VERSION ""

NS_ :

BS_:

BU_: DBG DRIVER IO MOTOR SENSOR MASTER GEO BLE

BO_ 1 BLE_START_STOP_CMD: 1 BLE
 SG_ BLE_START_STOP_CMD_start : 0|4@1+ (1,0) [0|1] "" MASTER
 SG_ BLE_START_STOP_CMD_reset : 4|4@1+ (1,0) [0|1] "" MASTER

BO_ 2 MASTER_SYS_STOP_CMD: 1 MASTER
 SG_ MASTER_SYS_STOP_CMD_stop : 0|8@1+ (1,0) [0|1] "" MOTOR

BO_ 212 BLE_GPS_DATA: 8 BLE
 SG_ BLE_GPS_long : 0|32@1- (0.000001,0) [0|0] "" GEO
 SG_ BLE_GPS_lat : 32|32@1- (0.000001,0) [0|0] "" GEO

BO_ 213 BLE_GPS_DATA_CNT: 1 BLE
 SG_ BLE_GPS_COUNT : 0|8@1+ (1,0) [0|0] "" GEO,SENSOR

BO_ 214 GEO_CURRENT_COORD: 8 GEO
 SG_ GEO_CURRENT_COORD_LONG : 0|32@1- (0.000001,0) [0|0] "" MASTER,BLE
 SG_ GEO_CURRENT_COORD_LAT : 32|32@1- (0.000001,0) [0|0] "" MASTER,BLE

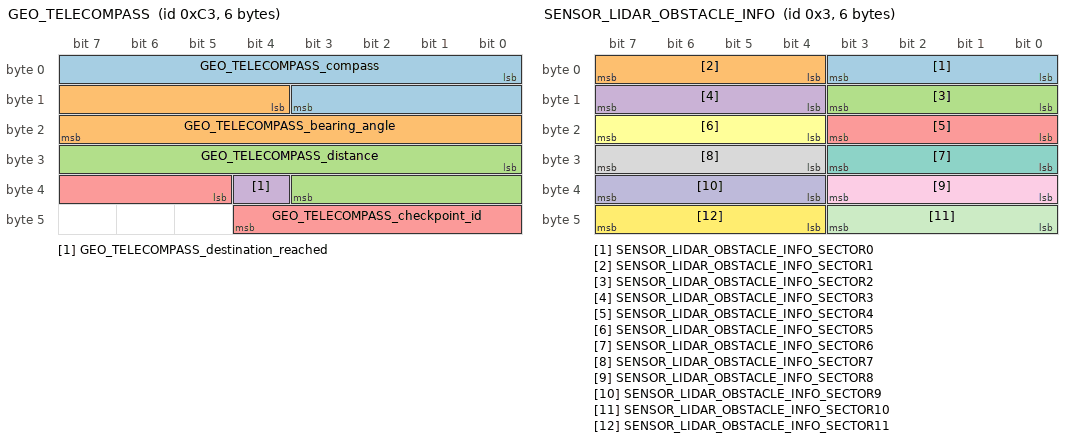
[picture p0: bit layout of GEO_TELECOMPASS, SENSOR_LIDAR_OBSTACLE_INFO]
BO_ 195 GEO_TELECOMPASS: 6 GEO
 SG_ GEO_TELECOMPASS_compass : 0|12@1+ (0.1,0) [0|360.0] "" MASTER,BLE
 SG_ GEO_TELECOMPASS_bearing_angle : 12|12@1+ (0.1,0) [0|360.0] "" MASTER,BLE
 SG_ GEO_TELECOMPASS_distance : 24|12@1+ (0.1,0) [0|0] "" MASTER,BLE
 SG_ GEO_TELECOMPASS_destination_reached : 36|1@1+ (1,0) [0|1] "" MASTER,BLE
 SG_ GEO_TELECOMPASS_checkpoint_id : 37|8@1+ (1,0) [0|0] "" MASTER,BLE,SENSOR

BO_ 196 GEO_TELEMETRY_LOCK: 1 GEO
 SG_ GEO_TELEMETRY_lock : 0|8@1+ (1,0) [0|0] "" MASTER,SENSOR,BLE

BO_ 197 BLE_CON_ST: 1 BLE
 SG_ BLE_ANDROID_CON_STATUS : 0|8@1+ (1,0) [0|0] "" SENSOR,MASTER

BO_ 3 SENSOR_LIDAR_OBSTACLE_INFO: 6 SENSOR
 SG_ SENSOR_LIDAR_OBSTACLE_INFO_SECTOR0 : 0|4@1+ (1,0) [0|12] "" MASTER,BLE
 SG_ SENSOR_LIDAR_OBSTACLE_INFO_SECTOR1 : 4|4@1+ (1,0) [0|12] "" MASTER,BLE
 SG_ SENSOR_LIDAR_OBSTACLE_INFO_SECTOR2 : 8|4@1+ (1,0) [0|12] "" MASTER,BLE
 SG_ SENSOR_LIDAR_OBSTACLE_INFO_SECTOR3 : 12|4@1+ (1,0) [0|12] "" MASTER,BLE
 SG_ SENSOR_LIDAR_OBSTACLE_INFO_SECTOR4 : 16|4@1+ (1,0) [0|12] "" MASTER,BLE
 SG_ SENSOR_LIDAR_OBSTACLE_INFO_SECTOR5 : 20|4@1+ (1,0) [0|12] "" MASTER,BLE
 SG_ SENSOR_LIDAR_OBSTACLE_INFO_SECTOR6 : 24|4@1+ (1,0) [0|12] "" MASTER,BLE
 SG_ SENSOR_LIDAR_OBSTACLE_INFO_SECTOR7 : 28|4@1+ (1,0) [0|12] "" MASTER,BLE
 SG_ SENSOR_LIDAR_OBSTACLE_INFO_SECTOR8 : 32|4@1+ (1,0) [0|12] "" MASTER,BLE
 SG_ SENSOR_LIDAR_OBSTACLE_INFO_SECTOR9 : 36|4@1+ (1,0) [0|12] "" MASTER,BLE
 SG_ SENSOR_LIDAR_OBSTACLE_INFO_SECTOR10 : 40|4@1+ (1,0) [0|12] "" MASTER,BLE
 SG_ SENSOR_LIDAR_OBSTACLE_INFO_SECTOR11 : 44|4@1+ (1,0) [0|12] "" MASTER,BLE

BO_ 17 MASTER_SPEED_STEER_CMD: 2 MASTER
 SG_ MASTER_SPEED_STEER_CMD_speed : 0|8@1- (1,0) [-100|100] "" MOTOR
 SG_ MASTER_SPEED_STEER_CMD_steer : 8|8@1- (1,0) [-100|100] "" MOTOR

BO_ 60 MASTER_SYS_START_CMD: 1 MASTER
 SG_ MASTER_SYS_START_CMD_start : 0|8@1+ (1,0) [0|1] "" SENSOR

BO_ 35 MOTOR_HEARTBEAT: 1 MOTOR
 SG_ MOTOR_HEARTBEAT_signal : 0|8@1+ (1,0) [0|255] "" MASTER

BO_ 36 SENSOR_HEARTBEAT: 1 SENSOR
 SG_ SENSOR_HEARTBEAT_signal : 0|8@1+ (1,0) [0|255] "" MASTER

BO_ 37 GEO_HEARTBEAT: 1 GEO
 SG_ GEO_HEARTBEAT_signal : 0|8@1+ (1,0) [0|255] "" MASTER

BO_ 38 BLE_HEARTBEAT: 1 BLE
 SG_ BLE_HEARTBEAT_signal : 0|8@1+ (1,0) [0|255] "" MASTER

BO_ 4 GEO_TURNING_ANGLE: 2 GEO
 SG_ GEO_TURNING_ANGLE_degree : 0|9@1- (1,0) [-180|180] "" MASTER,BLE

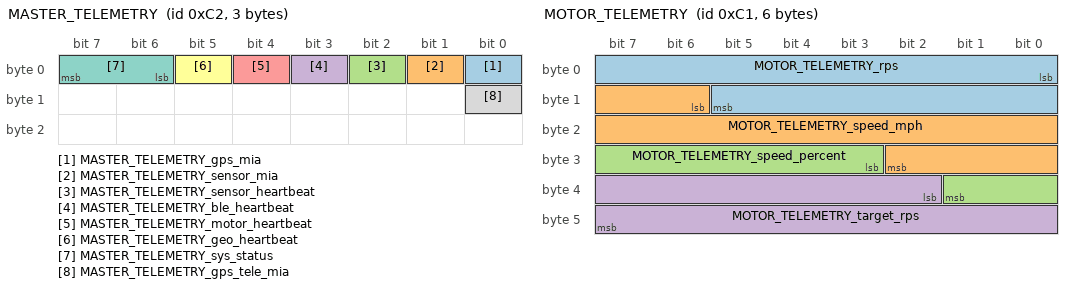
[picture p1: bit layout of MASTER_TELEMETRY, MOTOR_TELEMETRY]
BO_ 194 MASTER_TELEMETRY: 3 MASTER
 SG_ MASTER_TELEMETRY_gps_mia : 0|1@1+ (1,0) [0|1] "" BLE
 SG_ MASTER_TELEMETRY_sensor_mia : 1|1@1+ (1,0) [0|1] "" BLE
 SG_ MASTER_TELEMETRY_sensor_heartbeat : 2|1@1+ (1,0) [0|1] "" BLE
 SG_ MASTER_TELEMETRY_ble_heartbeat : 3|1@1+ (1,0) [0|1] "" BLE
 SG_ MASTER_TELEMETRY_motor_heartbeat : 4|1@1+ (1,0) [0|1] "" BLE
 SG_ MASTER_TELEMETRY_geo_heartbeat : 5|1@1+ (1,0) [0|1] "" BLE
 SG_ MASTER_TELEMETRY_sys_status : 6|2@1+ (1,0) [0|3] "" BLE
 SG_ MASTER_TELEMETRY_gps_tele_mia : 8|1@1+ (1,0) [0|1] "" BLE

BO_ 193 MOTOR_TELEMETRY: 6 MOTOR
 SG_ MOTOR_TELEMETRY_rps : 0|14@1+ (0.01,0) [0|100.00] "" MASTER
 SG_ MOTOR_TELEMETRY_speed_mph : 14|13@1+ (0.01,0) [0|70.00] "" MASTER
 SG_ MOTOR_TELEMETRY_speed_percent : 27|7@1+ (1,0) [0|100] "" MASTER
 SG_ MOTOR_TELEMETRY_target_rps : 34|14@1+ (0.01,0) [0|100.00] "" MASTER

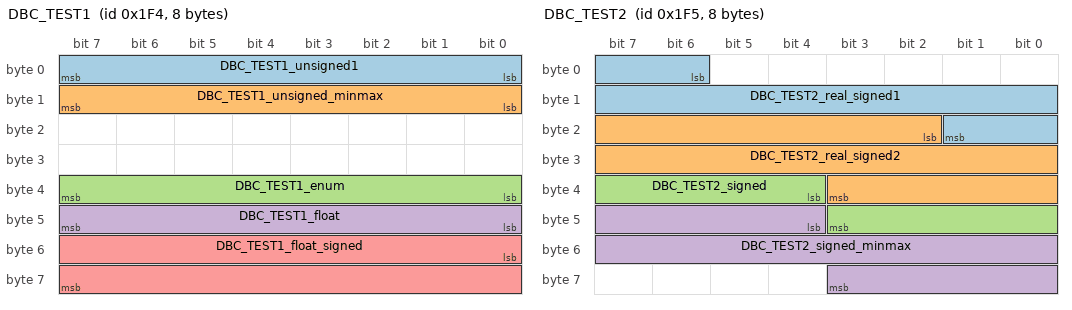
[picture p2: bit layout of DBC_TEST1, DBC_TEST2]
BO_ 500 DBC_TEST1: 8 IO
 SG_ DBC_TEST1_unsigned1 : 0|8@1+ (1,0) [0|0] "" DBG
 SG_ DBC_TEST1_unsigned_minmax : 8|8@1+ (1,0) [0|100] "" DBG
 SG_ DBC_TEST1_enum : 32|8@1+ (1,0) [0|0] "" DBG
 SG_ DBC_TEST1_float : 40|8@1+ (0.5,0) [0|0] "" DBG
 SG_ DBC_TEST1_float_signed : 48|16@1+ (0.001,0) [0|65.535] "" DBG

BO_ 501 DBC_TEST2: 8 IO
 SG_ DBC_TEST2_real_signed1 : 6|12@1- (1,0) [0|0] "" DBG
 SG_ DBC_TEST2_real_signed2 : 18|18@1- (1,0) [0|0] "" DBG
 SG_ DBC_TEST2_signed : 36|8@1+ (1,-128) [0|0] "" DBG
 SG_ DBC_TEST2_signed_minmax : 44|16@1+ (1,-32768) [-32768|32767] "" DBG

BO_ 502 DBC_TEST3: 8 IO
 SG_ DBC_TEST3_real_signed1 : 2|4@1- (1,-5) [0|0] "" DBG
 SG_ DBC_TEST3_real_signed2 : 8|8@1- (1,4) [0|0] "" DBG

BO_ 100 DRIVER_HEARTBEAT: 1 DRIVER
 SG_ DRIVER_HEARTBEAT_cmd : 0|8@1+ (1,0) [0|0] "" SENSOR,MOTOR

BO_ 101 MOTOR_CMD: 1 DRIVER
 SG_ MOTOR_CMD_steer : 0|4@1+ (1,-5) [-5|5] "" MOTOR
 SG_ MOTOR_CMD_drive : 4|4@1+ (1,0) [0|9] "" MOTOR

BO_ 400 MOTOR_STATUS: 3 MOTOR
 SG_ MOTOR_STATUS_wheel_error : 0|1@1+ (1,0) [0|0] "" DRIVER,IO
 SG_ MOTOR_STATUS_speed_kph : 8|16@1+ (0.001,0) [0|0] "kph" DRIVER,IO

BO_ 200 SENSOR_SONARS: 8 SENSOR
 SG_ SENSOR_SONARS_mux M : 0|4@1+ (1,0) [0|0] "" DRIVER,IO
 SG_ SENSOR_SONARS_err_count : 4|12@1+ (1,0) [0|0] "" DRIVER,IO
 SG_ SENSOR_SONARS_left m0 : 16|12@1+ (0.1,0) [0|0] "" DRIVER,IO
 SG_ SENSOR_SONARS_middle m0 : 28|12@1+ (0.1,0) [0|0] "" DRIVER,IO
 SG_ SENSOR_SONARS_right m0 : 40|12@1+ (0.1,0) [0|0] "" DRIVER,IO
 SG_ SENSOR_SONARS_rear m0 : 52|12@1+ (0.1,0) [0|0] "" DRIVER,IO
 SG_ SENSOR_SONARS_no_filt_left m1 : 16|12@1+ (0.1,0) [0|0] "" DBG
 SG_ SENSOR_SONARS_no_filt_middle m1 : 28|12@1+ (0.1,0) [0|0] "" DBG
 SG_ SENSOR_SONARS_no_filt_right m1 : 40|12@1+ (0.1,0) [0|0] "" DBG
 SG_ SENSOR_SONARS_no_filt_rear m1 : 52|12@1+ (0.1,0) [0|0] "" DBG

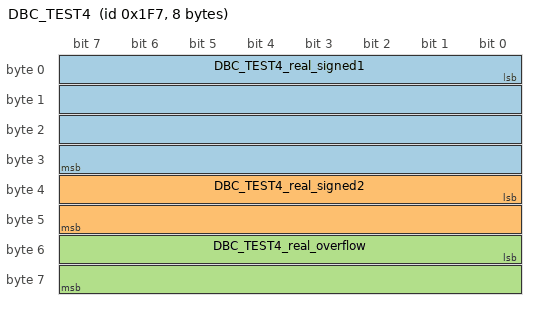
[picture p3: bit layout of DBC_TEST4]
BO_ 503 DBC_TEST4: 8 IO
 SG_ DBC_TEST4_real_signed1 : 0|32@1- (1,0) [0|0] "" DBG
 SG_ DBC_TEST4_real_signed2 : 32|16@1- (1,0) [-32768|32767] "" DBG
 SG_ DBC_TEST4_real_overflow : 48|16@1+ (1,0) [0|0] "" DBG

CM_ BU_ DRIVER "The driver controller driving the car";
CM_ BU_ MOTOR "The motor controller of the car";
CM_ BU_ SENSOR "The sensor controller of the car";
CM_ BO_ 100 "Sync message used to synchronize the controllers";

BA_DEF_ "BusType" STRING ;
BA_DEF_ BO_ "GenMsgCycleTime" INT 0 0;
BA_DEF_ SG_ "FieldType" STRING ;

BA_DEF_DEF_ "BusType" "CAN";
BA_DEF_DEF_ "FieldType" "";
BA_DEF_DEF_ "GenMsgCycleTime" 0;

BA_ "GenMsgCycleTime" BO_ 500 100;
BA_ "GenMsgCycleTime" BO_ 100 1000;
BA_ "GenMsgCycleTime" BO_ 101 100;
BA_ "GenMsgCycleTime" BO_ 400 100;
BA_ "GenMsgCycleTime" BO_ 200 100;
BA_ "FieldType" SG_ 500 DBC_TEST1_enum "DBC_TEST1_enum";
BA_ "FieldType" SG_ 100 DRIVER_HEARTBEAT_cmd "DRIVER_HEARTBEAT_cmd";

VAL_ 500 DBC_TEST1_enum 2 "DBC_TEST1_enum_val_two" 1 "DBC_TEST1_enum_val_one" ;
VAL_ 100 DRIVER_HEARTBEAT_cmd 2 "DRIVER_HEARTBEAT_cmd_REBOOT" 1 "DRIVER_HEARTBEAT_cmd_SYNC" 0 "DRIVER_HEARTBEAT_cmd_NOOP" ;
